AUTOSAR XML (schema 4-0-3)
package /ComponentTypes
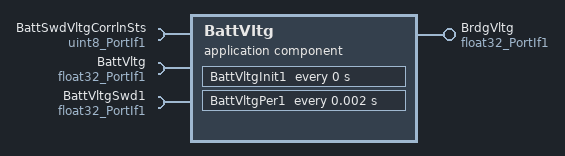
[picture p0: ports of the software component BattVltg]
  application sw component type BattVltg
    provide port BrdgVltg: nonqueued-sender-com-spec{data-element=Val, init-value=6}, provided-interface=float32_PortIf1
    require port BattSwdVltgCorrlnSts: nonqueued-receiver-com-spec{data-element=Val, filter=data-filter-type=ALWAYS, init-value=2}, required-interface=uint8_PortIf1
    require port BattVltg: nonqueued-receiver-com-spec{data-element=Val, filter=data-filter-type=ALWAYS, init-value=0}, required-interface=float32_PortIf1
    require port BattVltgSwd1: nonqueued-receiver-com-spec{data-element=Val, filter=data-filter-type=ALWAYS, init-value=0}, required-interface=float32_PortIf1
    behavior BattVltg_InternalBehavior
      timing event BattVltgInit1_InitEvent: start-on-event=BattVltgInit1, period=0
      timing event TMT_BattVltgPer1: start-on-event=BattVltgPer1, period=0.002
      runnable BattVltgInit1
      runnable BattVltgPer1
        data-receive-point-by-arguments:
          access REC_BattSwdVltgCorrlnSts_Val: accessed-variable=BattSwdVltgCorrlnSts.Val
          access REC_BattVltg_Val: accessed-variable=BattVltg.Val
          access REC_BattVltgSwd1_Val: accessed-variable=BattVltgSwd1.Val
        data-send-points:
          access SEND_BrdgVltg_Val: accessed-variable=BrdgVltg.Val
  swc implementation BattVltg_Implementation: behavior=BattVltg_InternalBehavior
    code-descriptors:
      code Default: artifact-descriptors=autosar-engineering-object={short-label=Default, category=SWSRC}
